VERSION ""

NS_ :

BS_:

BU_: TTC GatewayPC

BO_ 3221225472 VectorIndipendantSigMsg: 0 VectorXXX
 SG_ SteeringClutchCmd : 0|1@1+ (1,0) [0|0] "" VectorXXX
 SG_ CurtisDirection : 0|1@1+ (1,0) [0|0] "" VectorXXX
 SG_ CurtisMode12 : 0|1@1+ (1,0) [0|0] "" VectorXXX
 SG_ CurtisInhibit : 0|1@1+ (1,0) [0|0] "" VectorXXX
 SG_ CmdEngageBrake : 0|1@1+ (1,0) [0|0] "" VectorXXX
 SG_ CmdParkingBrake : 0|1@1+ (1,0) [0|0] "" VectorXXX
 SG_ CmdBrakeSwitch : 0|1@1+ (1,0) [0|0] "" VectorXXX
 SG_ CmdHorn : 0|1@1+ (1,0) [0|0] "" VectorXXX
 SG_ CmdLightBrake : 0|1@1+ (1,0) [0|0] "" VectorXXX
 SG_ CmdBlinkLeft : 0|1@1+ (1,0) [0|0] "" VectorXXX
 SG_ CmdBlinkRight : 0|1@1+ (1,0) [0|0] "" VectorXXX
 SG_ CmdBrightsOn : 0|1@1+ (1,0) [0|0] "" VectorXXX
 SG_ CmdLightReverse : 0|1@1+ (1,0) [0|0] "" VectorXXX
 SG_ CmdLightsTurnLeft : 0|1@1+ (1,0) [0|0] "" VectorXXX
 SG_ CmdLightsTurnRight : 0|1@1+ (1,0) [0|0] "" VectorXXX
 SG_ GatewayPcCmd : 0|1@1+ (1,0) [0|0] "" VectorXXX
 SG_ ServoBrakeStatus : 0|1@1+ (1,0) [0|0] "" VectorXXX
 SG_ CANThrottle : 0|1@1+ (1,0) [0|0] "" VectorXXX
 SG_ ProjCmd : 0|1@1+ (1,0) [0|0] "" VectorXXX
 SG_ CmdLightsStatusRed : 0|1@1- (1,0) [0|0] "" VectorXXX
 SG_ CmdLightsStatusYellow : 0|1@1+ (1,0) [0|0] "" VectorXXX
 SG_ CmdLightsStatusGreen : 0|1@1+ (1,0) [0|0] "" VectorXXX

BO_ 67 RawSignals: 2 TTC
 SG_ uint16EncoderRawValue : 0|16@1+ (1,0) [0|0] ""  GatewayPC

BO_ 66 RawSignalSteeringForce: 8 TTC
 SG_ uint32SignalSteeringForceB : 32|32@1+ (1,0) [0|0] ""  GatewayPC
 SG_ uint32SignalSteeringForceA : 0|32@1+ (1,0) [0|0] ""  GatewayPC

BO_ 65 RawSignalBreak: 8 TTC
 SG_ uint32SignalBrakeB : 32|32@1+ (1,0) [0|0] ""  GatewayPC
 SG_ uint32SignalBrakeA : 0|32@1+ (1,0) [0|0] ""  GatewayPC

BO_ 64 RawSignalThrottle: 8 TTC
 SG_ uint32SignalThrottleB : 32|32@1+ (1,0) [0|0] ""  GatewayPC
 SG_ uint32SignalThrottleA : 0|32@1+ (1,0) [0|0] ""  GatewayPC

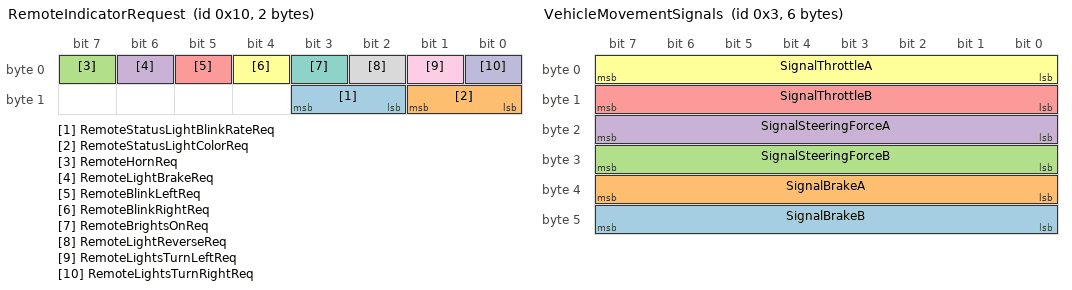
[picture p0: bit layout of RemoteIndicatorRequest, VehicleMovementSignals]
BO_ 16 RemoteIndicatorRequest: 2 GatewayPC
 SG_ RemoteStatusLightBlinkRateReq : 10|2@1+ (1,0) [0|0] ""  TTC
 SG_ RemoteStatusLightColorReq : 8|2@1+ (1,0) [0|0] ""  TTC
 SG_ RemoteHornReq : 7|1@1+ (1,0) [0|0] ""  TTC
 SG_ RemoteLightBrakeReq : 6|1@1+ (1,0) [0|0] ""  TTC
 SG_ RemoteBlinkLeftReq : 5|1@1+ (1,0) [0|0] ""  TTC
 SG_ RemoteBlinkRightReq : 4|1@1+ (1,0) [0|0] ""  TTC
 SG_ RemoteBrightsOnReq : 3|1@1+ (1,0) [0|0] ""  TTC
 SG_ RemoteLightReverseReq : 2|1@1+ (1,0) [0|0] ""  TTC
 SG_ RemoteLightsTurnLeftReq : 1|1@1+ (1,0) [0|0] ""  TTC
 SG_ RemoteLightsTurnRightReq : 0|1@1+ (1,0) [0|0] ""  TTC

BO_ 3 VehicleMovementSignals: 6 TTC
 SG_ SignalBrakeB : 40|8@1+ (1,0) [0|0] ""  GatewayPC
 SG_ SignalBrakeA : 32|8@1+ (1,0) [0|0] ""  GatewayPC
 SG_ SignalSteeringForceB : 24|8@1+ (1,0) [0|0] ""  GatewayPC
 SG_ SignalSteeringForceA : 16|8@1+ (1,0) [0|0] ""  GatewayPC
 SG_ SignalThrottleB : 8|8@1+ (1,0) [0|0] ""  GatewayPC
 SG_ SignalThrottleA : 0|8@1+ (1,0) [0|0] ""  GatewayPC

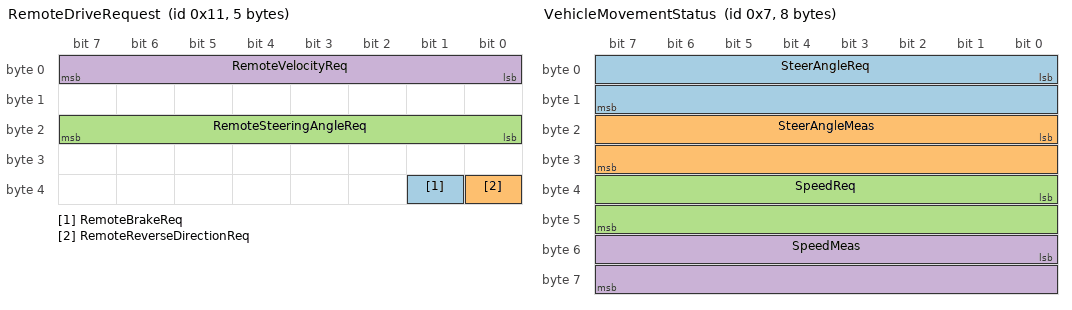
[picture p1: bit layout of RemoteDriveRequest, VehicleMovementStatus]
BO_ 17 RemoteDriveRequest: 5 GatewayPC
 SG_ RemoteBrakeReq : 33|1@1+ (1,0) [0|0] ""  TTC
 SG_ RemoteReverseDirectionReq : 32|1@1+ (1,0) [0|0] ""  TTC
 SG_ RemoteSteeringAngleReq : 16|8@1- (1,0) [0|0] ""  TTC
 SG_ RemoteVelocityReq : 0|8@1+ (1,0) [0|0] ""  TTC

BO_ 7 VehicleMovementStatus: 8 TTC
 SG_ SteerAngleReq : 0|16@1- (0.000381,0) [0|0] "rad"  GatewayPC
 SG_ SteerAngleMeas : 16|16@1- (0.000381,0) [0|0] "rad"  GatewayPC
 SG_ SpeedReq : 32|16@1- (0.001,0) [0|0] "km/h"  GatewayPC
 SG_ SpeedMeas : 48|16@1- (0.001,0) [0|0] "km/h"  GatewayPC

BO_ 2 GeneralVehicleStatus: 8 TTC
 SG_ Signal12Switch : 39|1@1+ (1,0) [0|0] ""  GatewayPC
 SG_ RequestZeroThrottle : 56|1@1+ (1,0) [0|0] "" VectorXXX
 SG_ RequestBrake : 57|1@1+ (1,0) [0|0] "" VectorXXX
 SG_ VehicleVelocitySignal : 48|8@1- (1,0) [0|0] ""  GatewayPC
 SG_ SteeringPositionSignal : 40|8@1- (1,0) [0|0] ""  GatewayPC
 SG_ SignalBrightsOn : 35|1@1+ (1,0) [0|0] ""  GatewayPC
 SG_ SignalRightTurn : 32|1@1+ (1,0) [0|0] ""  GatewayPC
 SG_ SignalLeftTurn : 33|1@1+ (1,0) [0|0] ""  GatewayPC
 SG_ SignalHorn : 38|1@1+ (1,0) [0|0] ""  GatewayPC
 SG_ SignalHazardLights : 37|1@1+ (1,0) [0|0] ""  GatewayPC
 SG_ SignalFogLights : 36|1@1+ (1,0) [0|0] ""  GatewayPC
 SG_ SignalDirection : 34|1@1+ (1,0) [0|0] ""  GatewayPC
 SG_ GlobalManSigMagBrake : 30|1@1+ (1,0) [0|0] ""  GatewayPC
 SG_ GlobalCurtisSigMagBrake : 31|1@1+ (1,0) [0|0] ""  GatewayPC
 SG_ SignalBrakeSwitch : 29|1@1+ (1,0) [0|0] ""  GatewayPC
 SG_ SignalSeatSwitch : 28|1@1+ (1,0) [0|0] ""  GatewayPC
 SG_ EStopStatus : 3|1@1+ (1,0) [0|0] ""  GatewayPC
 SG_ EnabledApplications : 16|12@1+ (1,0) [0|0] ""  GatewayPC
 SG_ SelectedApplication : 4|4@1+ (1,0) [0|0] ""  GatewayPC
 SG_ SelectedOpMode : 8|4@1+ (1,0) [0|0] ""  GatewayPC
 SG_ ActiveOpMode : 12|4@1+ (1,0) [0|0] ""  GatewayPC
 SG_ ButtonBlue : 0|1@1+ (1,0) [0|0] ""  GatewayPC
 SG_ ButtonYellow : 1|1@1+ (1,0) [0|0] ""  GatewayPC
 SG_ ButtonGreen : 2|1@1+ (1,0) [0|0] ""  GatewayPC

CM_ BU_ TTC "TTC580";
CM_ BU_ GatewayPC "Linux";
CM_ BO_ 3221225472 "This is a message for not used signals, created by Vector CANdb++ DBC OLE DB Provider.";
CM_ BO_ 7 "CAN6";
CM_ BO_ 2 "CAN6";
